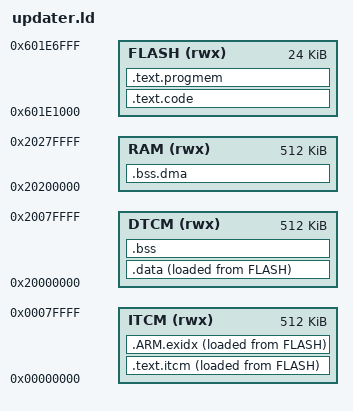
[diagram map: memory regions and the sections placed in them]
/* The updater's linker script: the Teensy core's imxrt1062.ld (Teensyduino 1.59) with the program placed in
 * the updater's slot, 0x601E1000 to 0x601E6FFF (include/boot_switch.h), rather than from 0x60000000. The
 * boot ROM never reads this program's own headers: the FlexSPI configuration block in sector 0 is the
 * firmware's, and the boot pointer in sector 1 is written by whoever flips the switch (the app, from the
 * page scripts/embed_updater.py makes). So the core's .flashconfig, .ivt, .bootdata and .csf are dropped,
 * and the entry is ResetHandler itself. Everything else is the core's, as it is. */

MEMORY
{
	ITCM (rwx):  ORIGIN = 0x00000000, LENGTH = 512K
	DTCM (rwx):  ORIGIN = 0x20000000, LENGTH = 512K
	RAM (rwx):   ORIGIN = 0x20200000, LENGTH = 512K
	FLASH (rwx): ORIGIN = 0x601E1000, LENGTH = 24K
}

ENTRY(ResetHandler)

SECTIONS
{
	/DISCARD/ : {
		*(.flashconfig)
		*(.ivt)
		*(.bootdata)
		*(.csf)
	}

	.text.code : {
		KEEP(*(.startup))
		*(.flashmem*)
		. = ALIGN(4);
		KEEP(*(.init))
		__preinit_array_start = .;
		KEEP (*(.preinit_array))
		__preinit_array_end = .;
		__init_array_start = .;
		KEEP (*(.init_array))
		__init_array_end = .;
		. = ALIGN(4);
	} > FLASH

	.text.progmem : {
		*(.progmem*)
		. = ALIGN(4);
	} > FLASH

	.text.itcm : {
		. = . + 32; /* MPU to trap NULL pointer deref */
		*(.fastrun)
		*(.text*)
		. = ALIGN(16);
	} > ITCM  AT> FLASH

	.ARM.exidx : {
		__exidx_start = .;
		*(.ARM.exidx* .ARM.extab.text* .gnu.linkonce.armexidx.*)
		__exidx_end = .;
	} > ITCM  AT> FLASH

	.data : {
		*(.endpoint_queue)
		*(SORT_BY_ALIGNMENT(SORT_BY_NAME(.rodata*)))
		*(SORT_BY_ALIGNMENT(SORT_BY_NAME(.data*)))
		KEEP(*(.vectorsram))
	} > DTCM  AT> FLASH

	.bss ALIGN(4) : {
		*(SORT_BY_ALIGNMENT(SORT_BY_NAME(.bss*)))
		*(SORT_BY_ALIGNMENT(SORT_BY_NAME(COMMON)))
		. = ALIGN(32);
		. = . + 32; /* MPU to trap stack overflow */
	} > DTCM

	.bss.dma (NOLOAD) : {
		*(.hab_log)
		*(.dmabuffers)
		. = ALIGN(32);
	} > RAM

	_stext = ADDR(.text.itcm);
	_etext = ADDR(.text.itcm) + SIZEOF(.text.itcm) + SIZEOF(.ARM.exidx);
	_stextload = LOADADDR(.text.itcm);

	_sdata = ADDR(.data);
	_edata = ADDR(.data) + SIZEOF(.data);
	_sdataload = LOADADDR(.data);

	_sbss = ADDR(.bss);
	_ebss = ADDR(.bss) + SIZEOF(.bss);

	_heap_start = ADDR(.bss.dma) + SIZEOF(.bss.dma);
	_heap_end = ORIGIN(RAM) + LENGTH(RAM);

	_itcm_block_count = (SIZEOF(.text.itcm) + SIZEOF(.ARM.exidx) + 0x7FFF) >> 15;
	_flexram_bank_config = 0xAAAAAAAA | ((1 << (_itcm_block_count * 2)) - 1);
	_estack = ORIGIN(DTCM) + ((16 - _itcm_block_count) << 15);

	/* the image's end, for the embed script's check (the core's _flashimagelen counts from 0x60000000) */
	_updater_end = LOADADDR(.data) + SIZEOF(.data);
	_flashimagelen = _updater_end - ORIGIN(FLASH);
	_teensy_model_identifier = 0x24;

	.debug_info     0 : { *(.debug_info) }
	.debug_abbrev   0 : { *(.debug_abbrev) }
	.debug_line     0 : { *(.debug_line) }
	.debug_frame    0 : { *(.debug_frame) }
	.debug_str      0 : { *(.debug_str) }
	.debug_loc      0 : { *(.debug_loc) }

}
